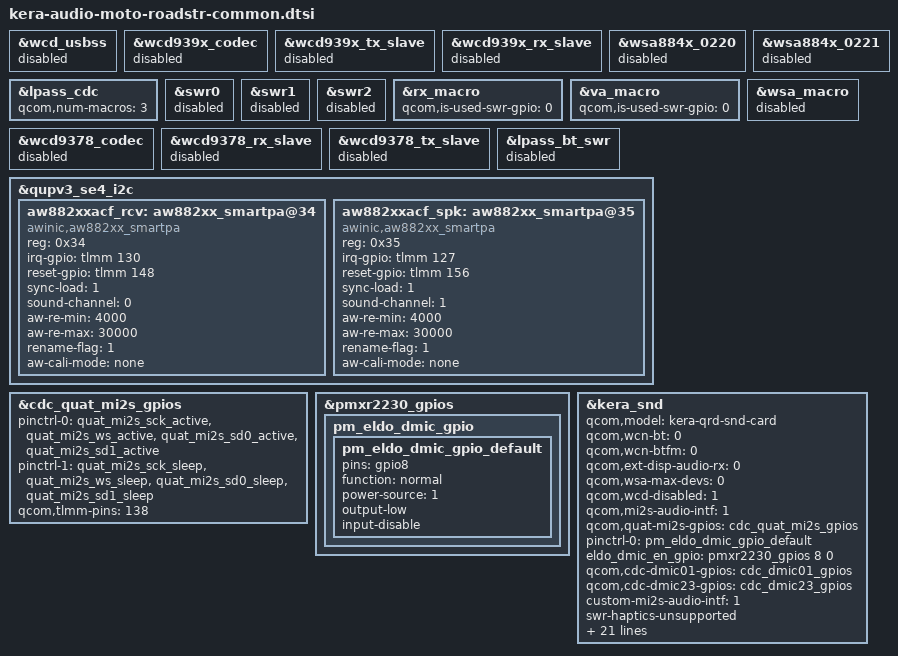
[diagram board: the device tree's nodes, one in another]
// SPDX-License-Identifier: BSD-3-Clause
/*
 * Copyright (c) 2023-2025 Qualcomm Innovation Center, Inc. All rights reserved.
 */

#include "kera-audio-overlay.dtsi"
#include "kera-audio-lpass-reg.dtsi"

&wcd_usbss {
	status = "disabled";
};

&wcd939x_codec {
	status = "disabled";
};

&wcd939x_tx_slave {
	status = "disabled";
};

&wcd939x_rx_slave {
	status = "disabled";
};

&wsa884x_0220 {
	status = "disabled";
};

&wsa884x_0221 {
	status = "disabled";
};

&lpass_cdc {
	qcom,num-macros = <3>;
};

&swr0 {
	status = "disabled";
};

&swr1 {
	status = "disabled";
};

&swr2 {
	status = "disabled";
};

&rx_macro {
	qcom,is-used-swr-gpio = <0>;
};

&va_macro {
	qcom,is-used-swr-gpio = <0>;
};

&wsa_macro {
	status = "disabled";
};

&wcd9378_codec {
        status = "disabled";
};

&wcd9378_rx_slave {
        status = "disabled";
};

&wcd9378_tx_slave {
        status = "disabled";
};

&lpass_bt_swr {
        status = "disabled";
};

&qupv3_se4_i2c {
	#address-cells = <1>;
	#size-cells = <0>;
	status = "ok";
        aw882xxacf_rcv: aw882xx_smartpa@34 { /* SPKL */
                  compatible = "awinic,aw882xx_smartpa";
                  reg = <0x34>;
                  irq-gpio = <&tlmm 130 0>;
                  reset-gpio = <&tlmm 148 0>;
                  sync-load = <1>;
                  sound-channel = <0>; /*0:pri_l 1:pri_r 2:sec_l 3:sec_r*/
                  aw-re-min = <4000>;
                  aw-re-max= <30000>;
                  rename-flag = <1>;
                  aw-cali-mode = "none";
                  status = "okay";
         };
         aw882xxacf_spk: aw882xx_smartpa@35 { /* SPKR */
                  compatible = "awinic,aw882xx_smartpa";
                  reg = <0x35>;
                  irq-gpio = <&tlmm 127 0>;
                  reset-gpio = <&tlmm 156 0>;
                  sync-load = <1>;
                  sound-channel = <1>; /*0:pri_l 1:pri_r 2:sec_l 3:sec_r*/
                  aw-re-min = <4000>;
                  aw-re-max= <30000>;
                  rename-flag = <1>;
                  aw-cali-mode = "none";
                  status = "okay";
         };
};

&cdc_quat_mi2s_gpios {
        status = "okay";
        pinctrl-0 = <&quat_mi2s_sck_active &quat_mi2s_ws_active
                         &quat_mi2s_sd0_active &quat_mi2s_sd1_active>;
        pinctrl-1 = <&quat_mi2s_sck_sleep &quat_mi2s_ws_sleep
                         &quat_mi2s_sd0_sleep &quat_mi2s_sd1_sleep>;
        qcom,tlmm-pins = <138>;
};

&pmxr2230_gpios {
	pm_eldo_dmic_gpio {
		pm_eldo_dmic_gpio_default: pm_eldo_dmic_gpio_default {
			pins = "gpio8";
			function = "normal";
			power-source = <1>;
			output-low;
			input-disable;
                };
        };
};

&kera_snd {
	qcom,model = "kera-qrd-snd-card";
	qcom,wcn-bt = <0>;
	qcom,wcn-btfm = <0>;
	qcom,ext-disp-audio-rx = <0>;
	qcom,wsa-max-devs = <0>;
	qcom,wcd-disabled = <1>;
	qcom,mi2s-audio-intf = <1>;
	qcom,quat-mi2s-gpios = <&cdc_quat_mi2s_gpios>;
	pinctrl-names = "default";
	pinctrl-0 = <&pm_eldo_dmic_gpio_default>;
	eldo_dmic_en_gpio = <&pmxr2230_gpios 8 0>;
	qcom,cdc-dmic01-gpios = <&cdc_dmic01_gpios>;
	qcom,cdc-dmic23-gpios = <&cdc_dmic23_gpios>;
	custom-mi2s-audio-intf = <1>;
	swr-haptics-unsupported;
	qcom,audio-routing =
		"TX DMIC0", "Digital Mic0",
		"TX DMIC1", "Digital Mic1",
		"TX DMIC2", "Digital Mic2",
		"TX DMIC3", "Digital Mic3",
		"TX DMIC4", "Digital Mic4",
		"TX DMIC5", "Digital Mic5",
		"TX DMIC6", "Digital Mic6",
		"TX DMIC7", "Digital Mic7",
		"RX_TX DEC0_INP", "TX DEC0 MUX",
		"RX_TX DEC1_INP", "TX DEC1 MUX",
		"RX_TX DEC2_INP", "TX DEC2 MUX",
		"RX_TX DEC3_INP", "TX DEC3 MUX",
		"VA SWR_INPUT", "VA_SWR_CLK",
		"VA_AIF1 CAP", "VA_SWR_CLK",
		"VA_AIF2 CAP", "VA_SWR_CLK",
		"VA_AIF3 CAP", "VA_SWR_CLK",
		"VA DMIC0", "Digital Mic0",
		"VA DMIC1", "Digital Mic1",
		"VA DMIC2", "Digital Mic2",
		"VA DMIC3", "Digital Mic3",
		"VA DMIC4", "Digital Mic4",
		"VA DMIC5", "Digital Mic5",
		"VA DMIC6", "Digital Mic6",
		"VA DMIC7", "Digital Mic7";
	asoc-codec  = <&stub_codec>, <&lpass_cdc>,
			<&aw882xxacf_rcv>, <&aw882xxacf_spk>;
	asoc-codec-names = "msm-stub-codec.1", "lpass-cdc",
			"aw882xx_smartpa_0", "aw882xx_smartpa_1";
};

